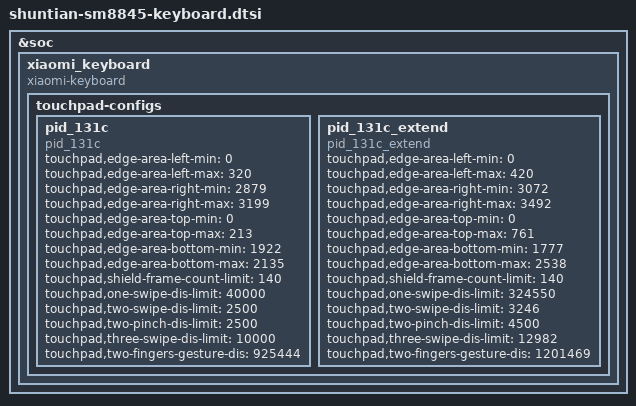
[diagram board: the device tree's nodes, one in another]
&soc {
	xiaomi_keyboard {
        compatible = "xiaomi-keyboard";
        status = "ok";
        touchpad-configs {
            pid_131c {
                compatible = "pid_131c";
                touchpad,edge-area-left-min = <0>;
                touchpad,edge-area-left-max = <320>;
                touchpad,edge-area-right-min = <2879>;
                touchpad,edge-area-right-max = <3199>;
                touchpad,edge-area-top-min = <0>;
                touchpad,edge-area-top-max = <213>;
                touchpad,edge-area-bottom-min = <1922>;
                touchpad,edge-area-bottom-max = <2135>;
                touchpad,shield-frame-count-limit = <140>;
                touchpad,one-swipe-dis-limit = <40000>;
                touchpad,two-swipe-dis-limit = <2500>;
                touchpad,two-pinch-dis-limit = <2500>;
                touchpad,three-swipe-dis-limit = <10000>;
                touchpad,two-fingers-gesture-dis = <925444>; // (sqrt(X^2+Y^2)*0.25)^2
            };
            pid_131c_extend {
                compatible = "pid_131c_extend";
                touchpad,edge-area-left-min = <0>;
                touchpad,edge-area-left-max = <420>;
                touchpad,edge-area-right-min = <3072>;
                touchpad,edge-area-right-max = <3492>;
                touchpad,edge-area-top-min = <0>;
                touchpad,edge-area-top-max = <761>;
                touchpad,edge-area-bottom-min = <1777>;
                touchpad,edge-area-bottom-max = <2538>;
                touchpad,shield-frame-count-limit = <140>;
                touchpad,one-swipe-dis-limit = <324550>;
                touchpad,two-swipe-dis-limit = <3246>;
                touchpad,two-pinch-dis-limit = <4500>;
                touchpad,three-swipe-dis-limit = <12982>;
                touchpad,two-fingers-gesture-dis = <1201469>; // (sqrt(X^2+Y^2)*0.25)^2
            };
        };
    };
};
